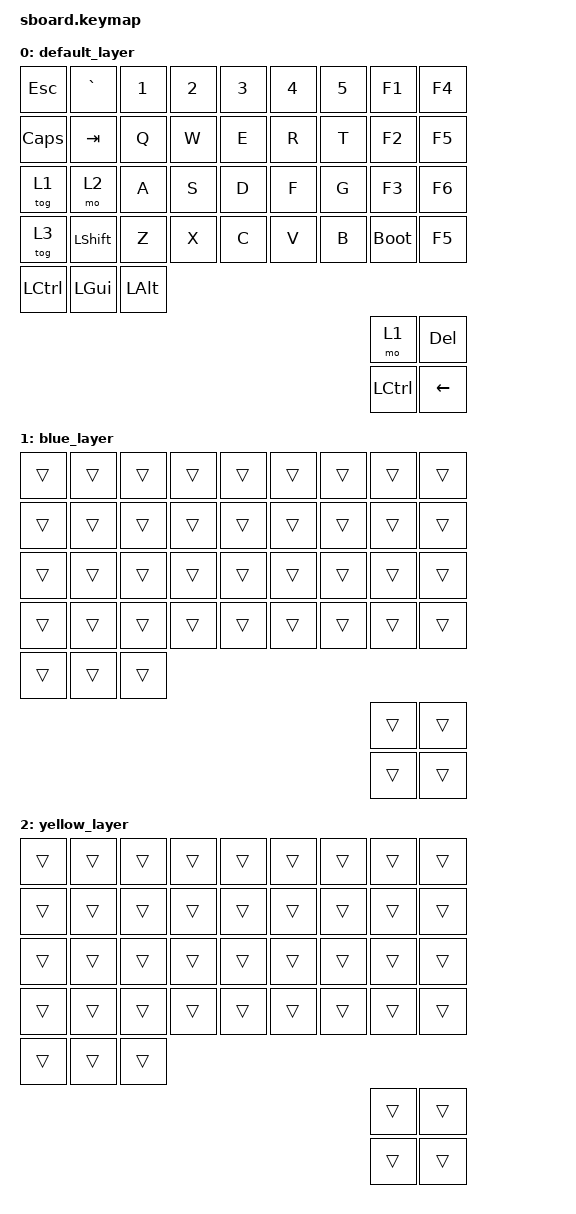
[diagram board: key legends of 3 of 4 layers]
#include <behaviors.dtsi>
#include <dt-bindings/zmk/keys.h>
#include <dt-bindings/zmk/bt.h>
#include <dt-bindings/zmk/ext_power.h>
#include <dt-bindings/zmk/mouse.h>
#include "mouse.dtsi"

#define BASE    0
#define BLUE    1
#define YELLOW  2
#define SETTING 3

/ {
    keymap {
        compatible = "zmk,keymap";

        default_layer {
// ------------------------------------------------------------------
// |  ESC  |  `    |  1  |  2   |  3   |  4   |  5   |   F1   |  F4 |
// | CAPS  | TAB   |  Q  |  W   |  E   |  R   |  T   |   F2   |  F5 |                  
// |  FnB  | FnY   |  A  |  S   |  D   |  F   |  G   |   F3   |  F6 |
// | Tri   | SHIFT |  Z  |  X   |  C   |  V   |  B   |   __   |  __ | 
// | CTRL  | GUI   | ALT |      |      |      |      |        |     |
// |       |       |     |      |      |      |      |   FnB  | Del |
// |       |       |     |      |      |      |      |  Ctrl  |  __ |                   
            bindings = <
&kp ESC     &kp GRAVE  &kp N1 &kp N2 &kp N3   &kp N4   &kp N5  &kp F1  &kp F4
&kp CAPS    &kp TAB    &kp Q  &kp W  &kp E    &kp R    &kp T   &kp F2  &kp F5       
&tog 1      &mo 2      &kp A  &kp S  &kp D    &kp F    &kp G   &kp F3  &kp F6
&tog 3      &kp LSHFT  &kp Z  &kp X  &kp C    &kp V    &kp B   &bootloader &kp F5
&kp LCTRL   &kp LGUI   &kp LALT  
                                                               &mo 1   &kp DEL
                                                               &kp LCTRL &kp LEFT
            >;

            sensor-bindings = <&inc_dec_msc SCROLL_UP  SCROLL_DOWN>;
        };

        blue_layer {
// ------------------------------------------------------------------
// |  ESC  |  `    |  1  |  2   |  3   |  4   |  5   |   F1   |  F4 |
// | CAPS  | TAB   |  Q  |  W   |  E   |  R   |  T   |   F2   |  F5 |                  
// |  FnB  | FnY   |  A  |  S   |  D   |  F   |  G   |   F3   |  F6 |
// | Tri   | SHIFT |  Z  |  X   |  C   |  V   |  B   |   __   |  __ | 
// | CTRL  | GUI   | ALT |      |      |      |      |        |     |
// |       |       |     |      |      |      |      |   FnB  | Del |
// |       |       |     |      |      |      |      |  Ctrl  |  __ |                   
            bindings = <
&trans      &trans  &trans  &trans  &trans    &trans    &trans  &trans  &trans
&trans      &trans  &trans  &trans  &trans    &trans    &trans  &trans  &trans       
&trans      &trans  &trans  &trans  &trans    &trans    &trans  &trans  &trans
&trans      &trans  &trans  &trans  &trans    &trans    &trans  &trans &trans
&trans      &trans  &trans  
                                                               &trans &trans
                                                               &trans &trans
            >;

            sensor-bindings = <&inc_dec_msc SCROLL_UP  SCROLL_DOWN>;
        };

        yellow_layer {            
            bindings = <
&trans      &trans  &trans  &trans  &trans    &trans    &trans  &trans  &trans
&trans      &trans  &trans  &trans  &trans    &trans    &trans  &trans  &trans       
&trans      &trans  &trans  &trans  &trans    &trans    &trans  &trans  &trans
&trans      &trans  &trans  &trans  &trans    &trans    &trans  &trans &trans
&trans      &trans  &trans  
                                                               &trans &trans
                                                               &trans &trans
            >;

            sensor-bindings = <&inc_dec_msc SCROLL_UP  SCROLL_DOWN>;
        };

        setting_layer {                 
            bindings = <
&bootloader &trans   &bt BT_SEL 0 &bt BT_SEL 1 &bt BT_SEL 2 &bt BT_SEL 3 &bt BT_SEL 4 &bt BT_SEL 5
&trans      &trans   &trans &trans &trans &trans &trans &trans  &trans
&trans      &trans   &trans &trans &trans &trans &trans &trans  &trans  
&trans      &trans   &trans &trans &trans &trans &trans &trans  &trans         
&trans      &trans   &trans  
                                                       &trans  &bt BT_CLR
                                                       &trans  &trans
            >;

            sensor-bindings = <&inc_dec_msc SCROLL_UP  SCROLL_DOWN>;
        };
    };
};



// Allow USB logging
&usbd {
	status = "okay";
	cdc_acm_uart: cdc_acm_uart {
		compatible = "zephyr,cdc-acm-uart";
		label = "CDC_ACM_0";
	};
};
